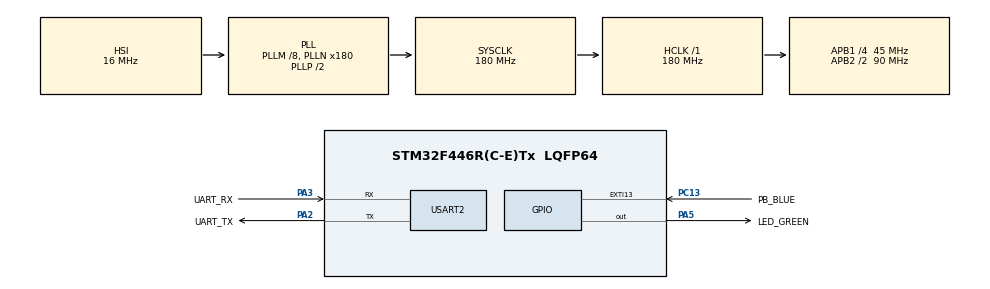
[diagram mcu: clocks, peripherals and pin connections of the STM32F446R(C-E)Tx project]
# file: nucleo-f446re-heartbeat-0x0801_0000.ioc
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IWDG.Prescaler=IWDG_PRESCALER_256
IWDG.Reload=0xfff
Mcu.Family=STM32F4
Mcu.Name=STM32F446R(C-E)Tx
Mcu.Package=LQFP64
NVIC.PriorityGroup=NVIC_PRIORITYGROUP_4
NVIC.TIM7_IRQn=true\:0\:0\:false\:true\:true\:1\:true\:true
PA13.GPIO_Label=SWDIO
PA13.Mode=Serial_Wire
PA13.Signal=SYS_JTMS-SWDIO
PA14.GPIO_Label=SWCLK
PA14.Mode=Serial_Wire
PA14.Signal=SYS_JTCK-SWCLK
PA2.GPIO_Label=UART_TX
PA2.Mode=Asynchronous
PA2.Signal=USART2_TX
PA3.GPIO_Label=UART_RX
PA3.Mode=Asynchronous
PA3.Signal=USART2_RX
PA5.GPIO_Label=LED_GREEN
PA5.Signal=GPIO_Output
PC13.GPIO_Label=PB_BLUE
PC13.Signal=GPXTI13
PH0-OSC_IN.GPIO_Label=OSC_IN
PH0-OSC_IN.Mode=HSE-External-Oscillator
PH0-OSC_IN.Signal=RCC_OSC_IN
PH1-OSC_OUT.GPIO_Label=OSC_OUT
PH1-OSC_OUT.Mode=HSE-External-Oscillator
PH1-OSC_OUT.Signal=RCC_OSC_OUT
ProjectManager.HeapSize=0x200
ProjectManager.StackSize=0x400
ProjectManager.TargetToolchain=STM32CubeIDE
RCC.AHBFreq_Value=180000000
RCC.APB1CLKDivider=RCC_HCLK_DIV4
RCC.APB1Freq_Value=45000000
RCC.APB1TimFreq_Value=90000000
RCC.APB2CLKDivider=RCC_HCLK_DIV2
RCC.APB2Freq_Value=90000000
RCC.APB2TimFreq_Value=180000000
RCC.CortexFreq_Value=180000000
RCC.HCLKFreq_Value=180000000
RCC.PLLM=8
RCC.PLLN=180
RCC.SYSCLKFreq_VALUE=180000000
RCC.SYSCLKSource=RCC_SYSCLKSOURCE_PLLCLK
RCC.USBFreq_Value=180000000
RCC.VCOOutputFreq_Value=360000000
TIM7.AutoReloadPreload=TIM_AUTORELOAD_PRELOAD_ENABLE
TIM7.Period=4999
TIM7.Prescaler=18000
TIM7.TIM_MasterOutputTrigger=TIM_TRGO_RESET
USART2.VirtualMode=VM_ASYNC
VP_IWDG_VS_IWDG.Mode=IWDG_Activate
VP_TIM7_VS_ClockSourceINT.Mode=Enable_Timer
board=custom

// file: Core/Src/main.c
/* USER CODE BEGIN Header */
/**
  ******************************************************************************
  * @file           : main.c
  * @brief          : Main program body
  ******************************************************************************
  * @attention
  *
  * <h2><center>&copy; Copyright (c) 2022 STMicroelectronics.
  * All rights reserved.</center></h2>
  *
  * This software component is licensed by ST under BSD 3-Clause license,
  * the "License"; You may not use this file except in compliance with the
  * License. You may obtain a copy of the License at:
  *                        opensource.org/licenses/BSD-3-Clause
  *
  ******************************************************************************
  */
/* USER CODE END Header */
#include "main.h"

/* USER CODE BEGIN Includes */
#include "global.h"
/* USER CODE END Includes */

IWDG_HandleTypeDef hiwdg;

TIM_HandleTypeDef htim7;

UART_HandleTypeDef huart2;

void SystemClock_Config(void);
static void MX_GPIO_Init(void);
static void MX_TIM7_Init(void);
static void MX_USART2_UART_Init(void);
static void MX_IWDG_Init(void);
static void MX_NVIC_Init(void);

int main(void)
{

  /* MCU Configuration--------------------------------------------------------*/

  /* Reset of all peripherals, Initializes the Flash interface and the Systick. */
  HAL_Init();

  /* Configure the system clock */
  SystemClock_Config();

  /* Initialize all configured peripherals */
  MX_GPIO_Init();
  MX_TIM7_Init();
  MX_USART2_UART_Init();
  MX_IWDG_Init();

  /* Initialize interrupts */
  MX_NVIC_Init();
  /* USER CODE BEGIN 2 */
  /****************************************************************************/
  /****************************************************************************/

  /* Run timer and its interrupt. */
  TIM_Run();

  /* Run application task. */
  TASK_Run(NULL);

  NO_RETURN_NEVER_COME_HERE();

  /****************************************************************************/
  /****************************************************************************/
  /* USER CODE END 2 */

  /* Infinite loop */
  while (1)
  {

  }
}

void SystemClock_Config(void)
{
  RCC_OscInitTypeDef RCC_OscInitStruct = {0};
  RCC_ClkInitTypeDef RCC_ClkInitStruct = {0};

  /** Configure the main internal regulator output voltage
  */
  __HAL_RCC_PWR_CLK_ENABLE();
  __HAL_PWR_VOLTAGESCALING_CONFIG(PWR_REGULATOR_VOLTAGE_SCALE1);
  /** Initializes the RCC Oscillators according to the specified parameters
  * in the RCC_OscInitTypeDef structure.
  */
  RCC_OscInitStruct.OscillatorType = RCC_OSCILLATORTYPE_HSI|RCC_OSCILLATORTYPE_LSI;
  RCC_OscInitStruct.HSIState = RCC_HSI_ON;
  RCC_OscInitStruct.HSICalibrationValue = RCC_HSICALIBRATION_DEFAULT;
  RCC_OscInitStruct.LSIState = RCC_LSI_ON;
  RCC_OscInitStruct.PLL.PLLState = RCC_PLL_ON;
  RCC_OscInitStruct.PLL.PLLSource = RCC_PLLSOURCE_HSI;
  RCC_OscInitStruct.PLL.PLLM = 8;
  RCC_OscInitStruct.PLL.PLLN = 180;
  RCC_OscInitStruct.PLL.PLLP = RCC_PLLP_DIV2;
  RCC_OscInitStruct.PLL.PLLQ = 2;
  RCC_OscInitStruct.PLL.PLLR = 2;
  if (HAL_RCC_OscConfig(&RCC_OscInitStruct) != HAL_OK)
  {
    Error_Handler();
  }
  /** Activate the Over-Drive mode
  */
  if (HAL_PWREx_EnableOverDrive() != HAL_OK)
  {
    Error_Handler();
  }
  /** Initializes the CPU, AHB and APB buses clocks
  */
  RCC_ClkInitStruct.ClockType = RCC_CLOCKTYPE_HCLK|RCC_CLOCKTYPE_SYSCLK
                              |RCC_CLOCKTYPE_PCLK1|RCC_CLOCKTYPE_PCLK2;
  RCC_ClkInitStruct.SYSCLKSource = RCC_SYSCLKSOURCE_PLLCLK;
  RCC_ClkInitStruct.AHBCLKDivider = RCC_SYSCLK_DIV1;
  RCC_ClkInitStruct.APB1CLKDivider = RCC_HCLK_DIV4;
  RCC_ClkInitStruct.APB2CLKDivider = RCC_HCLK_DIV2;

  if (HAL_RCC_ClockConfig(&RCC_ClkInitStruct, FLASH_LATENCY_5) != HAL_OK)
  {
    Error_Handler();
  }
}

/**
  * @brief NVIC Configuration.
  * @retval None
  */
static void MX_NVIC_Init(void)
{
  /* TIM7_IRQn interrupt configuration */
  HAL_NVIC_SetPriority(TIM7_IRQn, 0, 0);
  HAL_NVIC_EnableIRQ(TIM7_IRQn);
}

static void MX_IWDG_Init(void)
{

  hiwdg.Instance = IWDG;
  hiwdg.Init.Prescaler = IWDG_PRESCALER_256;
  hiwdg.Init.Reload = 0xfff;
  if (HAL_IWDG_Init(&hiwdg) != HAL_OK)
  {
    Error_Handler();
  }

}

static void MX_TIM7_Init(void)
{

  TIM_MasterConfigTypeDef sMasterConfig = {0};

  htim7.Instance = TIM7;
  htim7.Init.Prescaler = 18000;
  htim7.Init.CounterMode = TIM_COUNTERMODE_UP;
  htim7.Init.Period = 4999;
  htim7.Init.AutoReloadPreload = TIM_AUTORELOAD_PRELOAD_ENABLE;
  if (HAL_TIM_Base_Init(&htim7) != HAL_OK)
  {
    Error_Handler();
  }
  sMasterConfig.MasterOutputTrigger = TIM_TRGO_RESET;
  sMasterConfig.MasterSlaveMode = TIM_MASTERSLAVEMODE_DISABLE;
  if (HAL_TIMEx_MasterConfigSynchronization(&htim7, &sMasterConfig) != HAL_OK)
  {
    Error_Handler();
  }

}

static void MX_USART2_UART_Init(void)
{

  huart2.Instance = USART2;
  huart2.Init.BaudRate = 115200;
  huart2.Init.WordLength = UART_WORDLENGTH_8B;
  huart2.Init.StopBits = UART_STOPBITS_1;
  huart2.Init.Parity = UART_PARITY_NONE;
  huart2.Init.Mode = UART_MODE_TX_RX;
  huart2.Init.HwFlowCtl = UART_HWCONTROL_NONE;
  huart2.Init.OverSampling = UART_OVERSAMPLING_16;
  if (HAL_UART_Init(&huart2) != HAL_OK)
  {
    Error_Handler();
  }

}

static void MX_GPIO_Init(void)
{
  GPIO_InitTypeDef GPIO_InitStruct = {0};

  /* GPIO Ports Clock Enable */
  __HAL_RCC_GPIOC_CLK_ENABLE();
  __HAL_RCC_GPIOH_CLK_ENABLE();
  __HAL_RCC_GPIOA_CLK_ENABLE();

  /*Configure GPIO pin Output Level */
  HAL_GPIO_WritePin(LED_GREEN_GPIO_Port, LED_GREEN_Pin, GPIO_PIN_RESET);

  /*Configure GPIO pin : PB_BLUE_Pin */
  GPIO_InitStruct.Pin = PB_BLUE_Pin;
  GPIO_InitStruct.Mode = GPIO_MODE_IT_RISING;
  GPIO_InitStruct.Pull = GPIO_NOPULL;
  HAL_GPIO_Init(PB_BLUE_GPIO_Port, &GPIO_InitStruct);

  /*Configure GPIO pin : LED_GREEN_Pin */
  GPIO_InitStruct.Pin = LED_GREEN_Pin;
  GPIO_InitStruct.Mode = GPIO_MODE_OUTPUT_PP;
  GPIO_InitStruct.Pull = GPIO_NOPULL;
  GPIO_InitStruct.Speed = GPIO_SPEED_FREQ_LOW;
  HAL_GPIO_Init(LED_GREEN_GPIO_Port, &GPIO_InitStruct);

}

void Error_Handler(void)
{
  __disable_irq();
  while (1)
  {
  }
}
